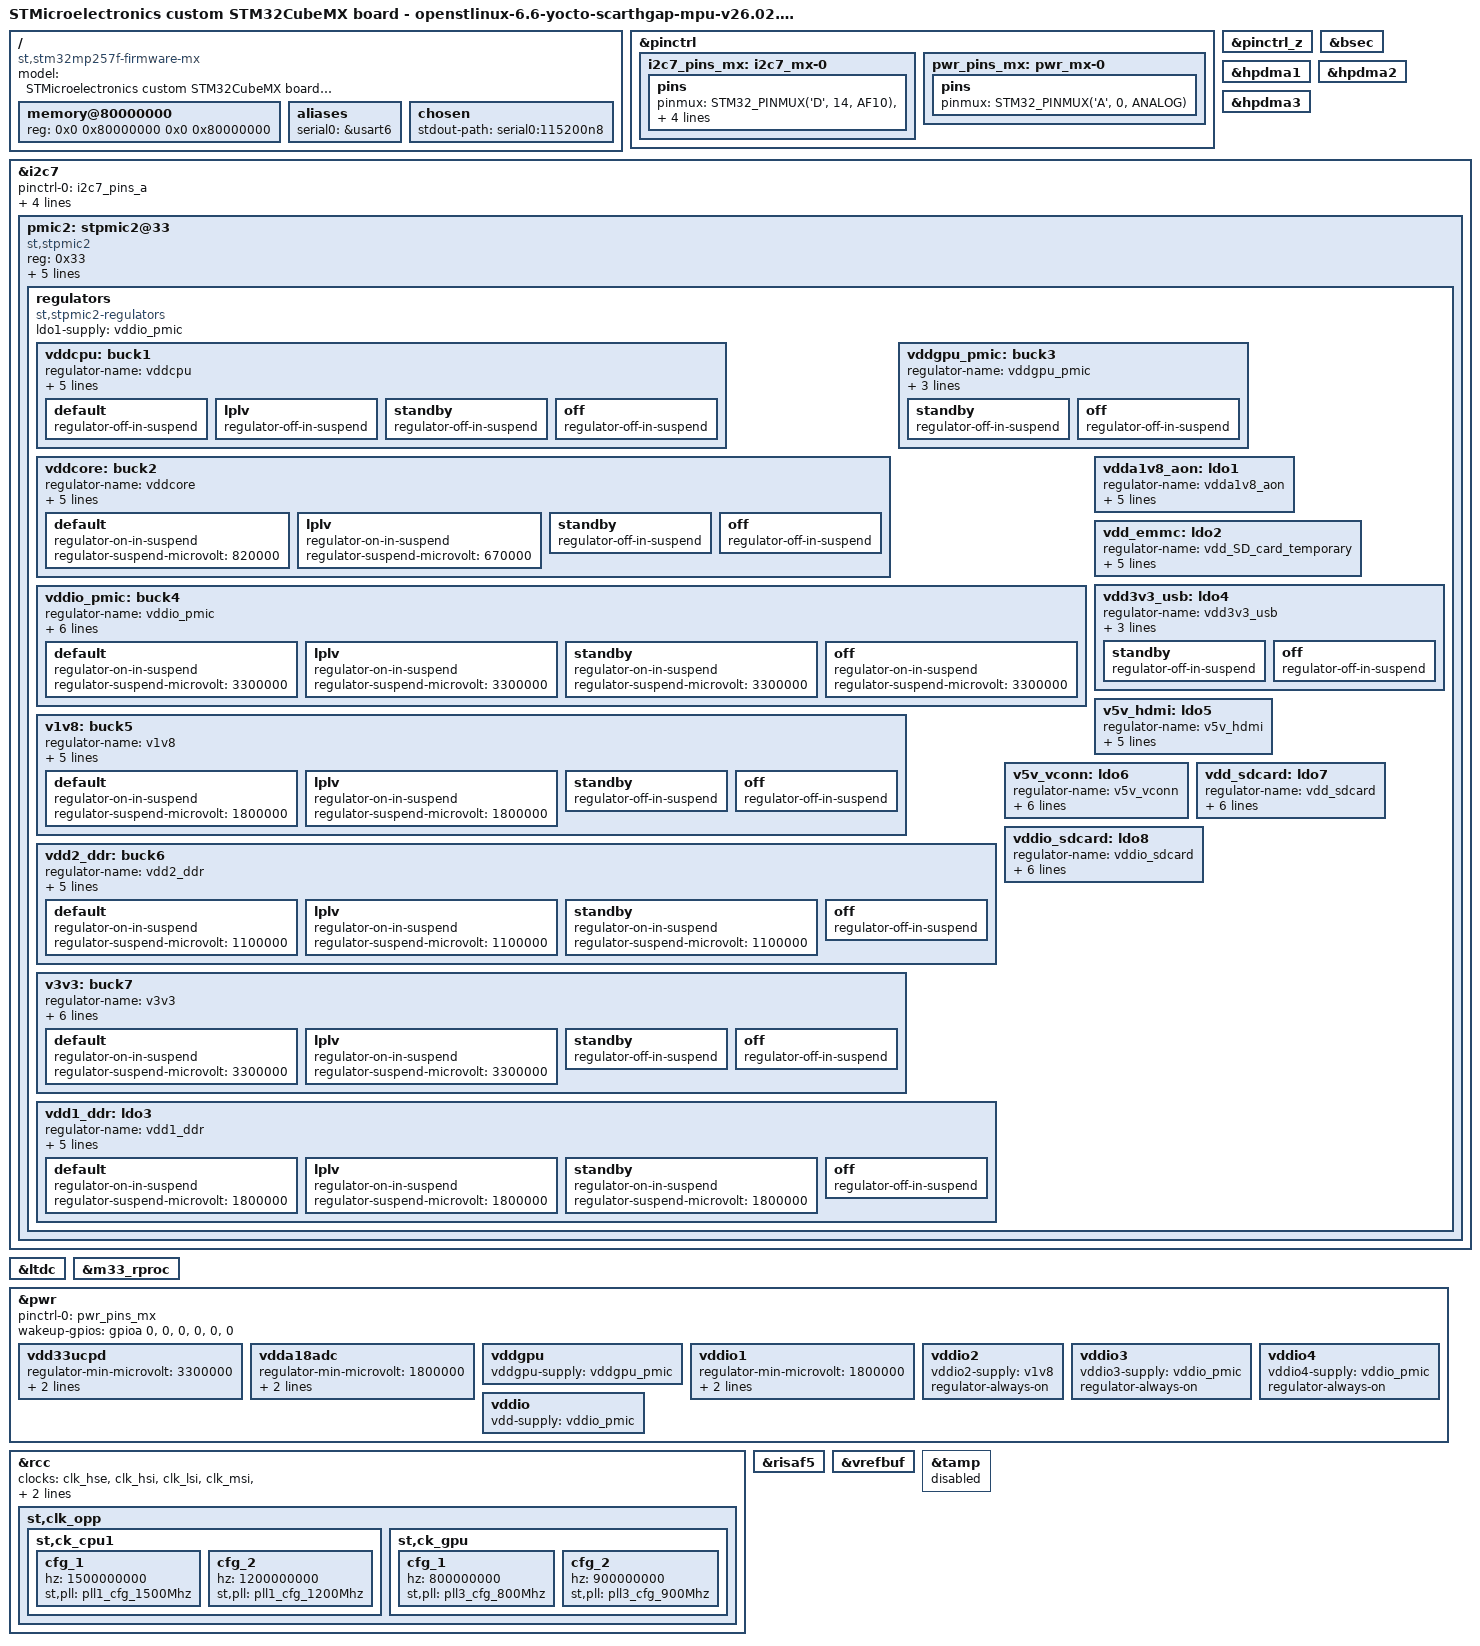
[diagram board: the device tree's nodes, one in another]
// SPDX-License-Identifier: (GPL-2.0-only OR BSD-3-Clause)
/*
 * Copyright (C) 2026, STMicroelectronics - All Rights Reserved
 * Author: STM32CubeMX code generation for STMicroelectronics.
 */

/* For more information on Device Tree configuration, please refer to
 * https://wiki.st.com/stm32mpu/wiki/Category:Device_tree_configuration
 */

/dts-v1/;

#include <dt-bindings/pinctrl/stm32-pinfunc.h>
#include <dt-bindings/clock/stm32mp25-clksrc.h>
#include "stm32mp257.dtsi"
#include "stm32mp25xf.dtsi"
#include "stm32mp257f-firmware-mx-rcc.dtsi"
#include "stm32mp257f-firmware-mx-resmem.dtsi"
#include "stm32mp257f-firmware-mx-rif.dtsi"
#include "stm32mp25xxak-pinctrl.dtsi"

/* USER CODE BEGIN includes */
/* USER CODE END includes */

/ {
	model = "STMicroelectronics custom STM32CubeMX board - openstlinux-6.6-yocto-scarthgap-mpu-v26.02.18";
	compatible = "st,stm32mp257f-firmware-mx", "st,stm32mp257";

	memory@80000000 {
		device_type = "memory";
		reg = <0x0 0x80000000 0x0 0x80000000>;

		/* USER CODE BEGIN memory */
		/* USER CODE END memory */
	};

	/* USER CODE BEGIN root */
	aliases {
		serial0 = &usart6;
	};

	chosen {
		stdout-path = "serial0:115200n8";
	};
	/* USER CODE END root */

}; /*root*/

&pinctrl {
	i2c7_pins_mx: i2c7_mx-0 {
		pins {
			pinmux = <STM32_PINMUX('D', 14, AF10)>, /* I2C7_SDA */
					 <STM32_PINMUX('D', 15, AF10)>; /* I2C7_SCL */
			bias-disable;
			drive-open-drain;
			slew-rate = <0>;
		};
	};

	pwr_pins_mx: pwr_mx-0 {
		pins {
			pinmux = <STM32_PINMUX('A', 0, ANALOG)>; /* PWR_WKUP1 */
		};
	};

	/* USER CODE BEGIN pinctrl */
	/* USER CODE END pinctrl */
};

&pinctrl_z {
	/* USER CODE BEGIN pinctrl_z */
	/* USER CODE END pinctrl_z */
};

&bsec {
	status = "okay";

	/* USER CODE BEGIN bsec */
	/* USER CODE END bsec */
};

&hpdma1 {
	status = "okay";

	/* USER CODE BEGIN hpdma1 */
	/* USER CODE END hpdma1 */
};

&hpdma2 {
	status = "okay";

	/* USER CODE BEGIN hpdma2 */
	/* USER CODE END hpdma2 */
};

&hpdma3 {
	status = "okay";

	/* USER CODE BEGIN hpdma3 */
	/* USER CODE END hpdma3 */
};

&i2c7 {
	pinctrl-names = "default";
	pinctrl-0 = <&i2c7_pins_mx>;
	status = "okay";

	/* USER CODE BEGIN i2c7 */
	pinctrl-names = "default", "sleep";
	pinctrl-0 = <&i2c7_pins_a>;
	pinctrl-1 = <&i2c7_sleep_pins_a>;
	i2c-scl-rising-time-ns = <185>;
	i2c-scl-falling-time-ns = <20>;
	clock-frequency = <400000>;
	status = "okay";
	#address-cells = <1>;
	#size-cells = <0>;

	pmic2: stpmic2@33 {
		compatible = "st,stpmic2";
		reg = <0x33>;
		interrupts-extended = <&exti1 52 IRQ_TYPE_EDGE_FALLING>;
		wakeup-source;
		st,pmic-it-id = <IT_PKEY_FA IT_PKEY_RI>;
		st,notif-it-id = <0 1>;
		status = "okay";

		regulators {
			compatible = "st,stpmic2-regulators";

			ldo1-supply = <&vddio_pmic>;
			vddcpu: buck1 {
				regulator-name = "vddcpu";
				regulator-min-microvolt = <800000>;
				regulator-max-microvolt = <910000>;
				regulator-always-on;
				st,pwrctrl-sel = <2>;
				st,pwrctrl-enable;

				default {
					regulator-off-in-suspend;
				};
				lplv {
					regulator-off-in-suspend;
				};
				standby {
					regulator-off-in-suspend;
				};
				off {
					regulator-off-in-suspend;
				};
			};
			vddcore: buck2 {
				regulator-name = "vddcore";
				regulator-min-microvolt = <820000>;
				regulator-max-microvolt = <820000>;
				regulator-always-on;
				st,pwrctrl-sel = <1>;
				st,pwrctrl-enable;

				default {
					regulator-on-in-suspend;
					regulator-suspend-microvolt = <820000>;
				};
				lplv {
					regulator-on-in-suspend;
					regulator-suspend-microvolt = <670000>;
				};
				standby {
					regulator-off-in-suspend;
				};
				off {
					regulator-off-in-suspend;
				};
			};
			vddgpu_pmic: buck3 {
				regulator-name = "vddgpu_pmic";
				regulator-min-microvolt = <800000>;
				regulator-max-microvolt = <900000>;
				regulator-over-current-protection;

				standby {
					regulator-off-in-suspend;
				};
				off {
					regulator-off-in-suspend;
				};
			};
			vddio_pmic: buck4 {
				regulator-name = "vddio_pmic";
				regulator-min-microvolt = <3300000>;
				regulator-max-microvolt = <3300000>;
				regulator-always-on;
				st,mask-reset;
				st,pwrctrl-sel = <1>;
				st,pwrctrl-enable;

				default {
					regulator-on-in-suspend;
					regulator-suspend-microvolt = <3300000>;
				};
				lplv {
					regulator-on-in-suspend;
					regulator-suspend-microvolt = <3300000>;
				};
				standby {
					regulator-on-in-suspend;
					regulator-suspend-microvolt = <3300000>;
				};
				off {
					/* ToDo: switch to LP */
					regulator-on-in-suspend;
					regulator-suspend-microvolt = <3300000>;
				};
			};
			v1v8: buck5 {
				regulator-name = "v1v8";
				regulator-min-microvolt = <1800000>;
				regulator-max-microvolt = <1800000>;
				regulator-always-on;
				st,pwrctrl-sel = <1>;
				st,pwrctrl-enable;

				default {
					regulator-on-in-suspend;
					regulator-suspend-microvolt = <1800000>;
				};
				lplv {
					regulator-on-in-suspend;
					regulator-suspend-microvolt = <1800000>;
				};
				standby {
					regulator-off-in-suspend;
				};
				off {
					regulator-off-in-suspend;
				};
			};
			vdd2_ddr: buck6 {
				regulator-name = "vdd2_ddr";
				regulator-min-microvolt = <1100000>;
				regulator-max-microvolt = <1100000>;
				regulator-always-on;
				st,pwrctrl-sel = <1>;
				st,pwrctrl-enable;

				default {
					regulator-on-in-suspend;
					regulator-suspend-microvolt = <1100000>;
				};
				lplv {
					regulator-on-in-suspend;
					regulator-suspend-microvolt = <1100000>;
				};
				standby {
					regulator-on-in-suspend;
					regulator-suspend-microvolt = <1100000>;
				};
				off {
					regulator-off-in-suspend;
				};
			};
			v3v3: buck7 {
				regulator-name = "v3v3";
				regulator-min-microvolt = <3300000>;
				regulator-max-microvolt = <3300000>;
				regulator-always-on;
				regulator-over-current-protection;
				st,pwrctrl-sel = <1>;
				st,pwrctrl-enable;

				default {
					regulator-on-in-suspend;
					regulator-suspend-microvolt = <3300000>;
				};
				lplv {
					regulator-on-in-suspend;
					regulator-suspend-microvolt = <3300000>;
				};
				standby {
					regulator-off-in-suspend;
				};
				off {
					regulator-off-in-suspend;
				};
			};
			vdda1v8_aon: ldo1 {
				regulator-name = "vdda1v8_aon";
				regulator-min-microvolt = <1800000>;
				regulator-max-microvolt = <1800000>;
				regulator-always-on;
				st,alternate-input-source;
				st,mask-reset;
			};
			vdd_emmc: ldo2 {
				regulator-name = "vdd_SD_card_temporary";
				regulator-min-microvolt = <3300000>;
				regulator-max-microvolt = <3300000>;
				regulator-over-current-protection;
				st,pwrctrl-sel = <3>;
				st,pwrctrl-reset;
			};
			vdd1_ddr: ldo3 {
				regulator-name = "vdd1_ddr";
				regulator-min-microvolt = <1800000>;
				regulator-max-microvolt = <1800000>;
				regulator-always-on;
				st,pwrctrl-sel = <1>;
				st,pwrctrl-enable;

				default {
					regulator-on-in-suspend;
					regulator-suspend-microvolt = <1800000>;
				};
				lplv {
					regulator-on-in-suspend;
					regulator-suspend-microvolt = <1800000>;
				};
				standby {
					regulator-on-in-suspend;
					regulator-suspend-microvolt = <1800000>;
				};
				off {
					regulator-off-in-suspend;
				};
			};
			vdd3v3_usb: ldo4 {
				regulator-name = "vdd3v3_usb";
				regulator-min-microvolt = <3300000>;
				regulator-max-microvolt = <3300000>;
				regulator-over-current-protection;

				standby {
					regulator-off-in-suspend;
				};
				off {
					regulator-off-in-suspend;
				};
			};
			v5v_hdmi: ldo5 {
				regulator-name = "v5v_hdmi";
				regulator-min-microvolt = <5000000>;
				regulator-max-microvolt = <5000000>;
				st,regulator-bypass-microvolt = <5000000>;
				st,pwrctrl-sel = <0>;
				st,pwrctrl-enable;
			};
			v5v_vconn: ldo6 {
				regulator-name = "v5v_vconn";
				regulator-min-microvolt = <4000000>;
				regulator-max-microvolt = <4000000>;
				regulator-always-on;
				st,regulator-bypass-microvolt = <4000000>;
				st,pwrctrl-sel = <0>;
				st,pwrctrl-reset;
			};
			vdd_sdcard: ldo7 {
				regulator-name = "vdd_sdcard";
				regulator-min-microvolt = <3300000>;
				regulator-max-microvolt = <3300000>;
				regulator-over-current-protection;
				st,regulator-bypass-microvolt = <3300000>;
				st,pwrctrl-sel = <3>;
				st,pwrctrl-reset;
			};
			vddio_sdcard: ldo8 {
				regulator-name = "vddio_sdcard";
				regulator-min-microvolt = <1800000>;
				regulator-max-microvolt = <3300000>;
				regulator-over-current-protection;
				st,regulator-bypass-microvolt = <3300000>;
				st,pwrctrl-sel = <3>;
				st,pwrctrl-reset;
			};
		};
	};
	/* USER CODE END i2c7 */
};

&ltdc {
	status = "okay";

	/* USER CODE BEGIN ltdc */
	/* USER CODE END ltdc */
};

&m33_rproc {
	status = "okay";

	/* USER CODE BEGIN m33_rproc */
	/* USER CODE END m33_rproc */
};

&pwr {
	pinctrl-names = "default";
	pinctrl-0 = <&pwr_pins_mx>;
	status = "okay";

	/* USER CODE BEGIN pwr */
	status = "okay";
	wakeup-gpios = <&gpioa 0 GPIO_ACTIVE_HIGH>, <0>, <0>, <0>, <0>, <0>;

	vdd33ucpd: vdd33ucpd {
		status = "okay";
		regulator-min-microvolt = <3300000>;
		regulator-max-microvolt = <3300000>;
		vdd33ucpd-supply = <&vdd3v3_usb>;
	};

	vdda18adc: vdda18adc {
		status = "okay";
		regulator-min-microvolt = <1800000>;
		regulator-max-microvolt = <1800000>;
		vdda18adc-supply = <&v1v8>;
	};

	vddgpu: vddgpu {
		status = "okay";
		vddgpu-supply = <&vddgpu_pmic>;
	};

	vddio1: vddio1 {
		status = "okay";
		regulator-min-microvolt = <1800000>;
		regulator-max-microvolt = <3300000>;
		vddio1-supply = <&vddio_sdcard>;
	};

	vddio2: vddio2 {
		status = "okay";
		vddio2-supply = <&v1v8>;
		regulator-always-on;
	};

	vddio3: vddio3 {
		status = "okay";
		vddio3-supply = <&vddio_pmic>;
		regulator-always-on;
	};

	vddio4: vddio4 {
		status = "okay";
		vddio4-supply = <&vddio_pmic>;
		regulator-always-on;
	};

	vddio: vddio {
		status = "okay";
		vdd-supply = <&vddio_pmic>;
	};
	/* USER CODE END pwr */
};

&rcc {
	status = "okay";

	/* USER CODE BEGIN rcc */
	clocks = <&clk_hse>, <&clk_hsi>, <&clk_lsi>, <&clk_msi>, <&clk_i2sin>;
	clock-names = "clk-hse", "clk-hsi", "clk-lsi", "clk-msi", "clk-i2sin";
	
	st,c1msrd = <2>;
	st,clk_opp {
		st,ck_cpu1 {
			cfg_1 {
				hz = <1500000000>;
				st,pll = <&pll1_cfg_1500Mhz>;
			};

			cfg_2 {
				hz = <1200000000>;
				st,pll = <&pll1_cfg_1200Mhz>;
			};
		};
		st,ck_gpu {
			cfg_1 {
				hz = <800000000>;
				st,pll = <&pll3_cfg_800Mhz>;
			};

			cfg_2 {
				hz = <900000000>;
				st,pll = <&pll3_cfg_900Mhz>;
			};
		};
	};
	/* USER CODE END rcc */
};

&risaf5 {
	status = "okay";

	/* USER CODE BEGIN risaf5 */
	/* USER CODE END risaf5 */
};

&vrefbuf {
	status = "okay";

	/* USER CODE BEGIN vrefbuf */
	/* USER CODE END vrefbuf */
};

/* USER CODE BEGIN addons */
&tamp {	
	status = "disabled";
};
/* USER CODE END addons */

